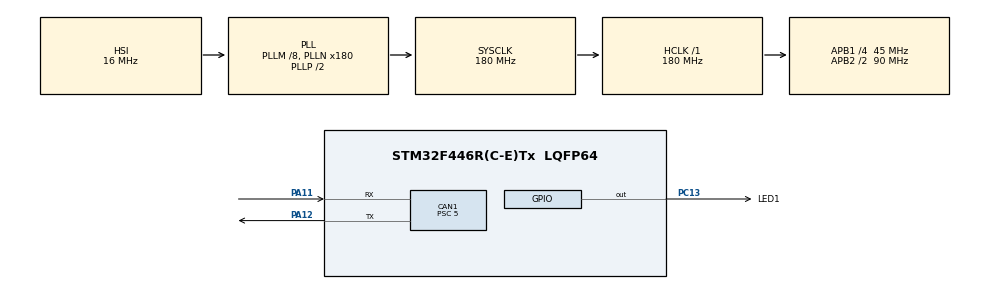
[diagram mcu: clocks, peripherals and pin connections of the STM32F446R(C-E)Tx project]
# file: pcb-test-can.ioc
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CAN1.BS1=CAN_BS1_6TQ
CAN1.BS2=CAN_BS2_2TQ
CAN1.CalculateBaudRate=1000000
CAN1.CalculateTimeBit=1000
CAN1.CalculateTimeQuantum=111.11111111111111
CAN1.Prescaler=5
Mcu.Family=STM32F4
Mcu.Name=STM32F446R(C-E)Tx
Mcu.Package=LQFP64
NVIC.PriorityGroup=NVIC_PRIORITYGROUP_4
PA11.Mode=CAN_Activate
PA11.Signal=CAN1_RX
PA12.Mode=CAN_Activate
PA12.Signal=CAN1_TX
PA13.Mode=Serial_Wire
PA13.Signal=SYS_JTMS-SWDIO
PA14.Mode=Serial_Wire
PA14.Signal=SYS_JTCK-SWCLK
PC13.GPIO_Label=LED1
PC13.Signal=GPIO_Output
ProjectManager.HeapSize=0x200
ProjectManager.StackSize=0x400
ProjectManager.TargetToolchain=STM32CubeIDE
RCC.AHBFreq_Value=180000000
RCC.APB1CLKDivider=RCC_HCLK_DIV4
RCC.APB1Freq_Value=45000000
RCC.APB1TimFreq_Value=90000000
RCC.APB2CLKDivider=RCC_HCLK_DIV2
RCC.APB2Freq_Value=90000000
RCC.APB2TimFreq_Value=180000000
RCC.CortexFreq_Value=180000000
RCC.HCLKFreq_Value=180000000
RCC.PLLM=8
RCC.PLLN=180
RCC.SYSCLKFreq_VALUE=180000000
RCC.SYSCLKSource=RCC_SYSCLKSOURCE_PLLCLK
RCC.USBFreq_Value=180000000
RCC.VCOOutputFreq_Value=360000000
board=custom

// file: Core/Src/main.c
/* USER CODE BEGIN Header */
/**
  ******************************************************************************
  * @file           : main.c
  * @brief          : Main program body
  ******************************************************************************
  * @attention
  *
  * Copyright (c) 2026 STMicroelectronics.
  * All rights reserved.
  *
  * This software is licensed under terms that can be found in the LICENSE file
  * in the root directory of this software component.
  * If no LICENSE file comes with this software, it is provided AS-IS.
  *
  ******************************************************************************
  */
/* USER CODE END Header */
#include "main.h"
#include "can.h"
#include "gpio.h"

/* USER CODE BEGIN Includes */
#include <string.h>
/* USER CODE END Includes */

/* USER CODE BEGIN PD */
#define CAN_TX_INTERVAL_MS 250
#define CAN_TX_TIMEOUT_MS  5     // An 8-byte frame at 1 Mbit/s takes ~0.13 ms
#define ERROR_BLINK_LOOPS  2000000 // Busy-wait count per LED toggle in Error_Handler (roughly 0.1 s at 180 MHz)
#define CAN_LOOPBACK_TEST  0     // 1 = controller ACKs its own frames (no bus needed), 0 = normal mode
/* USER CODE END PD */

void SystemClock_Config(void);
/* USER CODE BEGIN PFP */
static void CAN_Send_Frame(const uint8_t *data);
/* USER CODE END PFP */

int main(void)
{

  /* MCU Configuration--------------------------------------------------------*/

  /* Reset of all peripherals, Initializes the Flash interface and the Systick. */
  HAL_Init();

  /* USER CODE BEGIN Init */
  uint32_t last_can_tx_tick = HAL_GetTick();

  /* USER CODE END Init */

  /* Configure the system clock */
  SystemClock_Config();

  /* Initialize all configured peripherals */
  MX_GPIO_Init();
  MX_CAN1_Init();
  /* USER CODE BEGIN 2 */
  uint8_t data[8] = {0xDE, 0xAD, 0xBE, 0xEF, 0, 0, 0, 0};

#if CAN_LOOPBACK_TEST
  // Re-init in loopback mode here instead of in can.c so CubeMX regeneration doesn't undo it
  hcan1.Init.Mode = CAN_MODE_LOOPBACK;
  if(HAL_CAN_Init(&hcan1) != HAL_OK) {
	  Error_Handler();
  }
#endif

  if(HAL_CAN_Start(&hcan1) != HAL_OK) {
	  Error_Handler();
  }

  /* USER CODE END 2 */

  /* Infinite loop */
  /* USER CODE BEGIN WHILE */
  while (1)
  {
	if((HAL_GetTick() - last_can_tx_tick) >= CAN_TX_INTERVAL_MS)
	{
	  last_can_tx_tick = HAL_GetTick();
	  CAN_Send_Frame(data);
	}
    /* USER CODE END WHILE */

  }
}

void SystemClock_Config(void)
{
  RCC_OscInitTypeDef RCC_OscInitStruct = {0};
  RCC_ClkInitTypeDef RCC_ClkInitStruct = {0};

  /** Configure the main internal regulator output voltage
  */
  __HAL_RCC_PWR_CLK_ENABLE();
  __HAL_PWR_VOLTAGESCALING_CONFIG(PWR_REGULATOR_VOLTAGE_SCALE1);

  /** Initializes the RCC Oscillators according to the specified parameters
  * in the RCC_OscInitTypeDef structure.
  */
  RCC_OscInitStruct.OscillatorType = RCC_OSCILLATORTYPE_HSI;
  RCC_OscInitStruct.HSIState = RCC_HSI_ON;
  RCC_OscInitStruct.HSICalibrationValue = RCC_HSICALIBRATION_DEFAULT;
  RCC_OscInitStruct.PLL.PLLState = RCC_PLL_ON;
  RCC_OscInitStruct.PLL.PLLSource = RCC_PLLSOURCE_HSI;
  RCC_OscInitStruct.PLL.PLLM = 8;
  RCC_OscInitStruct.PLL.PLLN = 180;
  RCC_OscInitStruct.PLL.PLLP = RCC_PLLP_DIV2;
  RCC_OscInitStruct.PLL.PLLQ = 2;
  RCC_OscInitStruct.PLL.PLLR = 2;
  if (HAL_RCC_OscConfig(&RCC_OscInitStruct) != HAL_OK)
  {
    Error_Handler();
  }

  /** Activate the Over-Drive mode
  */
  if (HAL_PWREx_EnableOverDrive() != HAL_OK)
  {
    Error_Handler();
  }

  /** Initializes the CPU, AHB and APB buses clocks
  */
  RCC_ClkInitStruct.ClockType = RCC_CLOCKTYPE_HCLK|RCC_CLOCKTYPE_SYSCLK
                              |RCC_CLOCKTYPE_PCLK1|RCC_CLOCKTYPE_PCLK2;
  RCC_ClkInitStruct.SYSCLKSource = RCC_SYSCLKSOURCE_PLLCLK;
  RCC_ClkInitStruct.AHBCLKDivider = RCC_SYSCLK_DIV1;
  RCC_ClkInitStruct.APB1CLKDivider = RCC_HCLK_DIV4;
  RCC_ClkInitStruct.APB2CLKDivider = RCC_HCLK_DIV2;

  if (HAL_RCC_ClockConfig(&RCC_ClkInitStruct, FLASH_LATENCY_5) != HAL_OK)
  {
    Error_Handler();
  }
}

/* USER CODE BEGIN 4 */
static void CAN_Send_Frame(const uint8_t *data)
{
	CAN_TxHeaderTypeDef TxHeader;
	memset(&TxHeader, 0, sizeof(TxHeader));

    TxHeader.StdId = 101;
    TxHeader.IDE   = CAN_ID_STD;
    TxHeader.RTR   = CAN_RTR_DATA;
    TxHeader.DLC   = 8;

	uint32_t TxMailbox = 0;

	// Queue CAN frame if there's a free mailbox
    if (HAL_CAN_GetTxMailboxesFreeLevel(&hcan1) > 0 &&
        HAL_CAN_AddTxMessage(&hcan1, &TxHeader, data, &TxMailbox) == HAL_OK) {

    	// Wait for the transmission attempt to finish
    	uint32_t start = HAL_GetTick();
    	while (HAL_CAN_IsTxMessagePending(&hcan1, TxMailbox)) {
    		if ((HAL_GetTick() - start) >= CAN_TX_TIMEOUT_MS) {
    			HAL_CAN_AbortTxRequest(&hcan1, TxMailbox);
    			break;
    		}
    	}

    	// TXOK is only set if the frame went out and was ACKed by another node
    	uint32_t txok_bit = (TxMailbox == CAN_TX_MAILBOX0) ? CAN_TSR_TXOK0 :
    	                    (TxMailbox == CAN_TX_MAILBOX1) ? CAN_TSR_TXOK1 : CAN_TSR_TXOK2;
    	if (hcan1.Instance->TSR & txok_bit) {
    		HAL_GPIO_TogglePin(LED1_GPIO_Port, LED1_Pin); // Blink if frame was ACKed
    		return;
    	}
    }
    HAL_GPIO_WritePin(LED1_GPIO_Port, LED1_Pin, GPIO_PIN_SET); // Keep LED on if frame was not sent/ACKed
}
/* USER CODE END 4 */

void Error_Handler(void)
{
  /* USER CODE BEGIN Error_Handler_Debug */
  /* User can add his own implementation to report the HAL error return state */
  __disable_irq();
  while (1)
  {
	  // Fast blink so init errors are distinguishable from a solid "not sending" LED.
	  // Busy-wait because interrupts are off, so HAL_Delay() would hang.
	  HAL_GPIO_TogglePin(LED1_GPIO_Port, LED1_Pin);
	  for (volatile uint32_t i = 0; i < ERROR_BLINK_LOOPS; i++);
  }
  /* USER CODE END Error_Handler_Debug */
}
